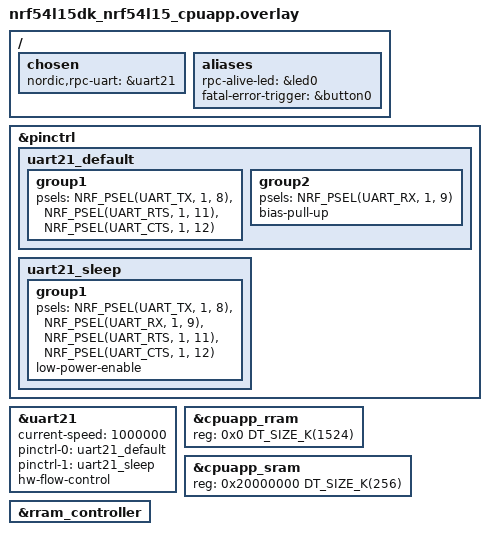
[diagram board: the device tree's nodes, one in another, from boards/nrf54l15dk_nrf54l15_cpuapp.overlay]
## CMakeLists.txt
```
#
# Copyright (c) 2024 Nordic Semiconductor ASA
#
# SPDX-License-Identifier: LicenseRef-Nordic-5-Clause
#
cmake_minimum_required(VERSION 3.20.0)

find_package(Zephyr REQUIRED HINTS $ENV{ZEPHYR_BASE})

project(protocols_serialization_server)

# NORDIC SDK APP START
target_sources(app PRIVATE src/main.c)

if(CONFIG_NRF_PS_SERVER_FATAL_ERROR_TRIGGER)
  target_sources(app PRIVATE src/fatal_error_trigger.c)
endif()

if(CONFIG_NRF_PS_SERVER_RPC_ALIVE_LED)
  # Wrap z_fatal_error to turn off the RPC alive LED on fatal error
  target_link_options(app INTERFACE -Wl,--wrap=z_fatal_error)
endif()
# NORDIC SDK APP END

# Link OpenThread CLI even though OPENTHREAD_SHELL is not selected
if(CONFIG_OPENTHREAD_RPC)
  target_link_libraries(zephyr PRIVATE openthread-cli-ftd)
endif()
```

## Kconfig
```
#
# Copyright (c) 2024 Nordic Semiconductor ASA
#
# SPDX-License-Identifier: LicenseRef-Nordic-5-Clause
#

menu "Protocols serialization server"

config NRF_PS_SERVER_FATAL_ERROR_TRIGGER
	bool "Fatal error trigger"
	depends on $(dt_alias_enabled,fatal-error-trigger)
	help
	  Enables triggering a fatal error by pressing the button selected with
	  "/aliases/fatal-error-trigger" DTS property. This feature can be used
	  to generate a core dump into a flash/RRAM partition. The core dump can
	  then be retrieved by the RPC client using the "Logging over RPC"
	  library.

config NRF_PS_SERVER_RPC_ALIVE_LED
	bool "RPC alive LED"
	default y
	depends on $(dt_alias_enabled,rpc-alive-led)
	help
	  Turns on the LED selected with "/aliases/rpc-alive-led" DTS property
	  when the UART transport is alive and ready to receive nRF RPC packets.

module = NRF_PS_SERVER
module-str = nrf_ps_server
source "${ZEPHYR_BASE}/subsys/logging/Kconfig.template.log_config"

endmenu # "Protocols serialization server"

config ZMS
	default y if (SOC_FLASH_NRF_RRAM || SOC_FLASH_NRF_MRAM)

config NVS
	default y if !(SOC_FLASH_NRF_RRAM || SOC_FLASH_NRF_MRAM)

config SHELL_BACKEND_SERIAL
	default n if NRF_RPC_UTILS_REMOTE_SHELL

if LOG

choice LOG_MODE
	default LOG_MODE_DEFERRED
endchoice

config LOG_BUFFER_SIZE
	default 8192

config LOG_FUNC_NAME_PREFIX_DBG
	default n

config LOG_BACKEND_RTT
	default n

config LOG_BACKEND_UART
	default n

endif # LOG

if SOC_NRF54L15

config BT_LONG_WQ_STACK_SIZE
	default 2048

choice TRUSTED_STORAGE_BACKEND_AEAD_KEY
	default TRUSTED_STORAGE_BACKEND_AEAD_KEY_HASH_UID if TRUSTED_STORAGE_BACKEND_AEAD
endchoice

endif # SOC_NRF54L15

menu "Zephyr Kernel"
source "Kconfig.zephyr"
endmenu
```

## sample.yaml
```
sample:
  name: Protocols serialization server sample
  description: Demonstrates serialization of Bluetooth LE and OpenThread API using
    nRF RPC

common:
  sysbuild: true
  build_only: true
  platform_allow:
    - nrf52840dk/nrf52840
    - nrf54l15dk/nrf54l15/cpuapp
  integration_platforms:
    - nrf52840dk/nrf52840
    - nrf54l15dk/nrf54l15/cpuapp
  tags:
    - ci_build
    - ci_samples_nrf_rpc

tests:
  sample.nrf_rpc.protocols_serialization.server.rpc_ble:
    extra_args: >
      SNIPPET="ble"
  sample.nrf_rpc.protocols_serialization.server.rpc_ot:
    extra_args: >
      SNIPPET="openthread"
  sample.nrf_rpc.protocols_serialization.server.rpc:
    extra_args: >
      SNIPPET="ble;openthread;debug;coex;log_rpc"
  sample.nrf_rpc.protocols_serialization.server.rpc_ci:
    extra_args: >
      SNIPPET="ble;openthread;debug;coex;log_rpc;ci-shell"
    extra_configs:
      - CONFIG_NRF_RPC_UTILS_CRASH_GEN=y
      - CONFIG_OPENTHREAD_RPC_ERASE_SETTINGS=y
```

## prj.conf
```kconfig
#
# Copyright (c) 2024 Nordic Semiconductor
#
# SPDX-License-Identifier: LicenseRef-Nordic-5-Clause
#
CONFIG_HEAP_MEM_POOL_SIZE=4096

CONFIG_NRF_RPC=y
CONFIG_NRF_RPC_CBOR=y
CONFIG_NRF_RPC_ZCBOR_BACKUPS=1
CONFIG_NRF_RPC_THREAD_STACK_SIZE=4096
CONFIG_NRF_RPC_GROUP_INIT_WAIT_TIME=-1
CONFIG_NRF_RPC_UART_TRANSPORT=y
CONFIG_NRF_RPC_UART_RELIABLE=y

CONFIG_UART_LINE_CTRL=y
CONFIG_UART_INTERRUPT_DRIVEN=y

CONFIG_NRF_RPC_UTILS=y
CONFIG_NRF_RPC_UTILS_SERVER=y
CONFIG_NRF_RPC_UTILS_DEV_INFO=y
CONFIG_NRF_RPC_UTILS_REMOTE_SHELL=y
CONFIG_NRF_RPC_UTILS_SYSTEM_HEALTH=y

CONFIG_SETTINGS=y
CONFIG_FLASH=y
CONFIG_FLASH_MAP=y
```

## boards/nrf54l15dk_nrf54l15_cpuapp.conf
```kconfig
#
# Copyright (c) 2024 Nordic Semiconductor
#
# SPDX-License-Identifier: LicenseRef-Nordic-5-Clause
#
CONFIG_MAIN_STACK_SIZE=4196
CONFIG_NRF_RPC_THREAD_STACK_SIZE=6144
```

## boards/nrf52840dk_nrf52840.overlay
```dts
/* Copyright (c) 2024 Nordic Semiconductor ASA
 *
 * SPDX-License-Identifier: LicenseRef-Nordic-5-Clause
 */

 / {
	chosen {
		nordic,rpc-uart = &uart1;
	};

	aliases {
		rpc-alive-led = &led0;
		fatal-error-trigger = &button0;
	};
};

&uart1 {
	status = "okay";
	hw-flow-control;
	current-speed = <1000000>;
};

&uart1_default {
	group1 {
		psels = <NRF_PSEL(UART_TX, 1, 2)>,
			<NRF_PSEL(UART_RTS, 1, 3)>,
			<NRF_PSEL(UART_CTS, 1, 4)>;
	};
	group2 {
		psels = <NRF_PSEL(UART_RX, 1, 1)>;
		bias-pull-up;
	};
};

&uart1_sleep {
	group1 {
		psels = <NRF_PSEL(UART_RX, 1, 1)>,
			<NRF_PSEL(UART_TX, 1, 2)>,
			<NRF_PSEL(UART_RTS, 1, 3)>,
			<NRF_PSEL(UART_CTS, 1, 4)>;
		low-power-enable;
	};
};
```

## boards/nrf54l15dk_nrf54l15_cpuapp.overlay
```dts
/* Copyright (c) 2024 Nordic Semiconductor ASA
 *
 * SPDX-License-Identifier: LicenseRef-Nordic-5-Clause
 */

 / {
	chosen {
		nordic,rpc-uart = &uart21;
	};

	aliases {
		rpc-alive-led = &led0;
		fatal-error-trigger = &button0;

		/* delete all buttons except button0 to free GPIO pins assigned to uart21 below */
		/delete-property/ sw1;
		/delete-property/ sw2;
		/delete-property/ sw3;
	};
};

/delete-node/ &button1;
/delete-node/ &button2;
/delete-node/ &button3;

&pinctrl {
	uart21_default: uart21_default {
		group1 {
			psels = <NRF_PSEL(UART_TX, 1, 8)>,
				<NRF_PSEL(UART_RTS, 1, 11)>,
				<NRF_PSEL(UART_CTS, 1, 12)>;
		};
		group2 {

			psels = <NRF_PSEL(UART_RX, 1, 9)>;
			bias-pull-up;
		};
	};

	uart21_sleep: uart21_sleep {
		group1 {
			psels = <NRF_PSEL(UART_TX, 1, 8)>,
				<NRF_PSEL(UART_RX, 1, 9)>,
				<NRF_PSEL(UART_RTS, 1, 11)>,
				<NRF_PSEL(UART_CTS, 1, 12)>;
			low-power-enable;
		};
	};
};

&uart21 {
	status = "okay";
	current-speed = <1000000>;
	pinctrl-0 = <&uart21_default>;
	pinctrl-1 = <&uart21_sleep>;
	pinctrl-names = "default", "sleep";
	hw-flow-control;
};

/* restore full RRAM and SRAM space - by default some parts are dedicated to FLRP */
&cpuapp_rram {
	reg = <0x0 DT_SIZE_K(1524)>;
};

&cpuapp_sram {
	reg = <0x20000000 DT_SIZE_K(256)>;
	ranges = <0x0 0x20000000  0x40000>;
};

&rram_controller {
	/delete-node/ cpuflpr_sram;
	/delete-node/ cpuflpr_rram;
};
```

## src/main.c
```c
/*
 * Copyright (c) 2024 Nordic Semiconductor ASA
 *
 * SPDX-License-Identifier: LicenseRef-Nordic-5-Clause
 */

#include <zephyr/drivers/gpio.h>
#include <zephyr/logging/log.h>

#include <nrf_rpc.h>

LOG_MODULE_REGISTER(nrf_ps_server, CONFIG_NRF_PS_SERVER_LOG_LEVEL);

static void err_handler(const struct nrf_rpc_err_report *report)
{
	LOG_ERR("nRF RPC error %d ocurred. See nRF RPC logs for more details", report->code);
}

#ifdef CONFIG_NRF_PS_SERVER_RPC_ALIVE_LED
void nrf_rpc_uart_initialized_hook(const struct device *uart_dev)
{
	const struct gpio_dt_spec alive_gpio = GPIO_DT_SPEC_GET(DT_ALIAS(rpc_alive_led), gpios);
	int ret;

	__ASSERT_NO_MSG(uart_dev == DEVICE_DT_GET(DT_CHOSEN(nordic_rpc_uart)));
	ret = gpio_pin_configure_dt(&alive_gpio, GPIO_OUTPUT_ACTIVE);

	if (ret) {
		LOG_ERR("Failed to configure RPC alive GPIO: %d", ret);
	}
}

void __real_z_fatal_error(unsigned int reason, const struct arch_esf *esf);

void __wrap_z_fatal_error(unsigned int reason, const struct arch_esf *esf)
{
	const struct gpio_dt_spec alive_gpio = GPIO_DT_SPEC_GET(DT_ALIAS(rpc_alive_led), gpios);

	(void)gpio_pin_configure_dt(&alive_gpio, GPIO_OUTPUT_INACTIVE);

	__real_z_fatal_error(reason, esf);
}
#endif

int main(void)
{
	int ret;

	LOG_INF("Initializing RPC server");

	ret = nrf_rpc_init(err_handler);

	if (ret != 0) {
		LOG_ERR("RPC init failed");
	}

	LOG_INF("RPC server ready");

	return 0;
}
```

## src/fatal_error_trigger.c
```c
/*
 * Copyright (c) 2024 Nordic Semiconductor ASA
 *
 * SPDX-License-Identifier: LicenseRef-Nordic-5-Clause
 */

#include <zephyr/drivers/gpio.h>
#include <zephyr/init.h>
#include <zephyr/logging/log.h>
#include <zephyr/sys/util_macro.h>

LOG_MODULE_DECLARE(nrf_ps_server, CONFIG_NRF_PS_SERVER_LOG_LEVEL);

const struct gpio_dt_spec gpio_pin = GPIO_DT_SPEC_GET(DT_ALIAS(fatal_error_trigger), gpios);
static struct gpio_callback gpio_cb;

static void trigger_handler(const struct device *port, struct gpio_callback *cb,
			    gpio_port_pins_t pins)
{
	ARG_UNUSED(port);
	ARG_UNUSED(cb);
	ARG_UNUSED(pins);

	LOG_ERR("Fatal error button pressed - triggering k_oops");
	k_oops();
}

static int trigger_init(void)
{
	int rc;

	if (!gpio_is_ready_dt(&gpio_pin)) {
		return -ENODEV;
	}

	rc = gpio_pin_configure_dt(&gpio_pin, GPIO_INPUT);
	if (rc) {
		return rc;
	}

	gpio_init_callback(&gpio_cb, trigger_handler, BIT(gpio_pin.pin));

	rc = gpio_add_callback_dt(&gpio_pin, &gpio_cb);
	if (rc) {
		return rc;
	}

	rc = gpio_pin_interrupt_configure_dt(&gpio_pin, GPIO_INT_EDGE_TO_ACTIVE);
	if (rc) {
		return rc;
	}

	return 0;
}

SYS_INIT(trigger_init, APPLICATION, CONFIG_APPLICATION_INIT_PRIORITY);
```
